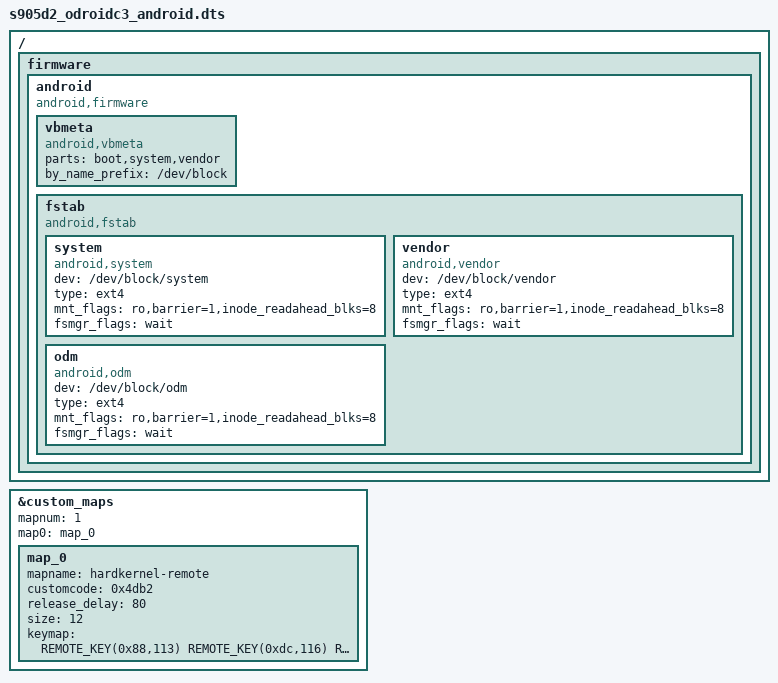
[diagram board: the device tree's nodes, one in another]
/*
 * arch/arm64/boot/dts/amlogic/s905d2_odroidc3_android.dts
 *
 * Copyright (C) 2018 Hardkernel Co., Ltd. All rights reserved.
 *
 * This program is free software; you can redistribute it and/or modify
 * it under the terms of the GNU General Public License as published by
 * the Free Software Foundation; either version 2 of the License, or
 * (at your option) any later version.
 *
 * This program is distributed in the hope that it will be useful, but WITHOUT
 * ANY WARRANTY; without even the implied warranty of MERCHANTABILITY or
 * FITNESS FOR A PARTICULAR PURPOSE.  See the GNU General Public License for
 * more details.
 *
 */

#include "s905d2_odroidc3.dts"

/ {
	firmware {
		android {
			compatible = "android,firmware";
			vbmeta {
				compatible = "android,vbmeta";
				parts = "boot,system,vendor";
				by_name_prefix="/dev/block";
			};
			fstab {
				compatible = "android,fstab";
				system {
					compatible = "android,system";
					dev = "/dev/block/system";
					type = "ext4";
					mnt_flags = "ro,barrier=1,inode_readahead_blks=8";
					fsmgr_flags = "wait";
				};
				vendor {
					compatible = "android,vendor";
					dev = "/dev/block/vendor";
					type = "ext4";
					mnt_flags = "ro,barrier=1,inode_readahead_blks=8";
					fsmgr_flags = "wait";
				};
				odm {
					compatible = "android,odm";
					dev = "/dev/block/odm";
					type = "ext4";
					mnt_flags = "ro,barrier=1,inode_readahead_blks=8";
					fsmgr_flags = "wait";
				};
			};
		};
	};
};

&custom_maps {
	mapnum = <1>;
	map0 = <&map_0>;
	map_0: map_0 {
		mapname = "hardkernel-remote";
		customcode = <0x4db2>;
		release_delay = <80>;
		size  = <12>;
		keymap = <REMOTE_KEY(0x88,113)
			REMOTE_KEY(0xdc,116)
			REMOTE_KEY(0xc5,139)
			REMOTE_KEY(0x9a,158)
			REMOTE_KEY(0xca,103)
			REMOTE_KEY(0x99,105)
			REMOTE_KEY(0xc1,106)
			REMOTE_KEY(0xd2,108)
			REMOTE_KEY(0x80,104)
			REMOTE_KEY(0x81,109)
			REMOTE_KEY(0x82,102)
			REMOTE_KEY(0xce,97)>;
	};
};
